AUTOSAR XML (schema 00048)
package /ComponentTypes
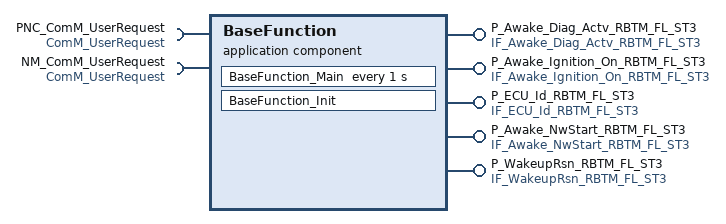
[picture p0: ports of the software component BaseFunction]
  application sw component type BaseFunction
    5 x provide port:
      P_Awake_Diag_Actv_RBTM_FL_ST3: nonqueued-sender-com-spec{data-element=Awake_Diag_Actv_RBTM_FL_ST3, init-value=constant-reference=XDIS_h5tcyk98kzbgrc5svasomeyt}, provided-interface=IF_Awake_Diag_Actv_RBTM_FL_ST3  # Stay awake for diagnostics active
      P_Awake_Ignition_On_RBTM_FL_ST3: nonqueued-sender-com-spec{data-element=Awake_Ignition_On_RBTM_FL_ST3, init-value=constant-reference=XDIS_h5tcyk98kzbgrc5svasomeyt}, provided-interface=IF_Awake_Ignition_On_RBTM_FL_ST3  # Stay awake for ignition on
      P_ECU_Id_RBTM_FL_ST3: nonqueued-sender-com-spec{data-element=ECU_Id_RBTM_FL_ST3, init-value=constant-reference=XDIS_ac2wq8fsnomfy8b1d5s468o4x}, provided-interface=IF_ECU_Id_RBTM_FL_ST3  # ECU identifier
      P_Awake_NwStart_RBTM_FL_ST3: nonqueued-sender-com-spec{data-element=Awake_NwStart_RBTM_FL_ST3, init-value=constant-reference=XDIS_h5tcyk98kzbgrc5svasomeyt}, provided-interface=IF_Awake_NwStart_RBTM_FL_ST3  # Stay awake for network startup
      P_WakeupRsn_RBTM_FL_ST3: nonqueued-sender-com-spec{data-element=WakeupRsn_RBTM_FL_ST3, init-value=constant-reference=XDIS_bggrcvuxyaw47ntt1npaw992u}, provided-interface=IF_WakeupRsn_RBTM_FL_ST3  # Wakeup reason
    require port PNC_ComM_UserRequest: required-com-specs=[GetRequestedComMode, GetMaxComMode, GetCurrentComMode, RequestComMode, GetCurrentPNCComMode], required-interface=ComM_UserRequest
    require port NM_ComM_UserRequest: required-com-specs=[GetRequestedComMode, GetMaxComMode, GetCurrentComMode, RequestComMode, GetCurrentPNCComMode], required-interface=ComM_UserRequest
    behavior BaseFunction_InternalBehavior: data-type-mapping=DataTypeMappings_DEV
      init event BaseFunction_App_CT_InitEvent: start-on-event=BaseFunction_Init
      timing event TMT_BaseFunction_App_Main: start-on-event=BaseFunction_Main, period=1
      explicit-inter-runnable-variables:
        data NmTimer: type=uint16, init-value=0
      runnable BaseFunction_Init
        read-local-variables:
          access Read_NmTimer: accessed-variable=NmTimer
        written-local-variables:
          access WRITE_NmTimer: accessed-variable=NmTimer
      runnable BaseFunction_Main
        data-send-points:
          5 x access:
            SEND_P_Awake_Diag_Actv_RBTM_FL_ST3_Awake_Diag_Actv_RBTM_FL_ST3: accessed-variable=P_Awake_Diag_Actv_RBTM_FL_ST3.Awake_Diag_Actv_RBTM_FL_ST3
            SEND_P_Awake_Ignition_On_RBTM_FL_ST3_Awake_Ignition_On_RBTM_FL_ST3: accessed-variable=P_Awake_Ignition_On_RBTM_FL_ST3.Awake_Ignition_On_RBTM_FL_ST3
            SEND_P_Awake_NwStart_RBTM_FL_ST3_Awake_NwStart_RBTM_FL_ST3: accessed-variable=P_Awake_NwStart_RBTM_FL_ST3.Awake_NwStart_RBTM_FL_ST3
            SEND_P_ECU_Id_RBTM_FL_ST3_ECU_Id_RBTM_FL_ST3: accessed-variable=P_ECU_Id_RBTM_FL_ST3.ECU_Id_RBTM_FL_ST3
            SEND_P_WakeupRsn_RBTM_FL_ST3_WakeupRsn_RBTM_FL_ST3: accessed-variable=P_WakeupRsn_RBTM_FL_ST3.WakeupRsn_RBTM_FL_ST3
        read-local-variables:
          access Read_NmTimer: accessed-variable=NmTimer
        sync call SC_NM_ComM_UserRequest_RequestComMode: operation=NM_ComM_UserRequest.RequestComMode
        sync call SC_PNC_ComM_UserRequest_RequestComMode: operation=PNC_ComM_UserRequest.RequestComMode
        written-local-variables:
          access WRITE_NmTimer: accessed-variable=NmTimer
  swc implementation BaseFunction_Implementation: behavior=BaseFunction_InternalBehavior
